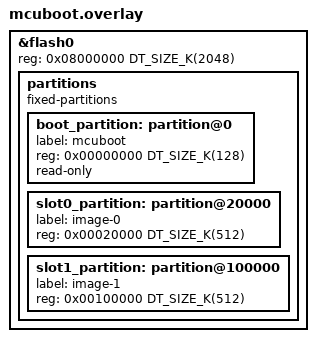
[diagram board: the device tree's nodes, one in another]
/*
 * Flash partition layout shared with MCUboot.
 * flash0 extended to 2MB: slot0 in bank 0, slot1 in bank 1.
 *
 * Remove ranges from flash0 to prevent DT_FIXED_PARTITION_ADDR from
 * double-adding the flash base address.
 */
&flash0 {
    reg = <0x08000000 DT_SIZE_K(2048)>;
    /delete-property/ ranges;

    partitions {
        compatible = "fixed-partitions";
        #address-cells = <1>;
        #size-cells = <1>;
        ranges;

        boot_partition: partition@0 {
            label = "mcuboot";
            reg = <0x00000000 DT_SIZE_K(128)>;
            read-only;
        };

        slot0_partition: partition@20000 {
            label = "image-0";
            reg = <0x00020000 DT_SIZE_K(512)>;
        };

        slot1_partition: partition@100000 {
            label = "image-1";
            reg = <0x00100000 DT_SIZE_K(512)>;
        };
    };
};
